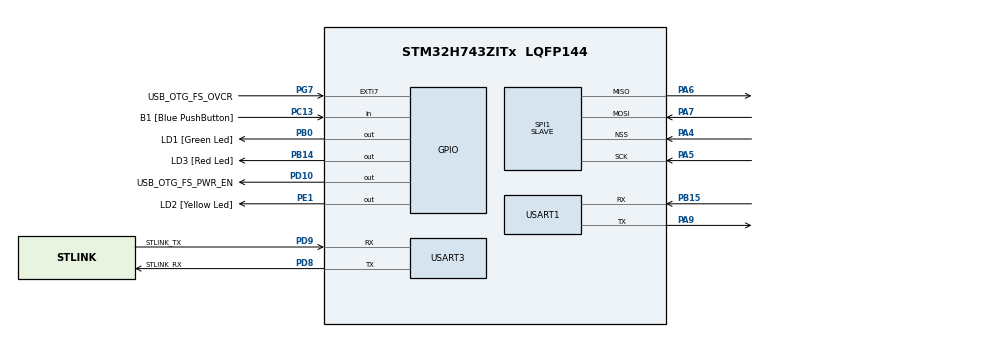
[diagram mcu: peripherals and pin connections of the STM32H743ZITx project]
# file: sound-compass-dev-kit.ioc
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FREERTOS.Queues01=executiveMessageQueue,16,uint16_t,0,Static,executiveMessageQueueBuffer,myQueue01ControlBlock
FREERTOS.Tasks01=defaultTask,24,1024,StartDefaultTask,Default,NULL,Static,defaultTaskBuffer,defaultTaskControlBlock
FREERTOS.Timers01=myTimer01,Callback01,osTimerPeriodic,Default,NULL,Static,myTimer01ControlBlock
FREERTOS.configENABLE_FPU=1
FREERTOS.configUSE_NEWLIB_REENTRANT=1
Mcu.Family=STM32H7
Mcu.Name=STM32H743ZITx
Mcu.Package=LQFP144
NVIC.PriorityGroup=NVIC_PRIORITYGROUP_4
NVIC.SPI1_IRQn=true\:5\:0\:false\:false\:true\:true\:true\:true\:true
NVIC.TIM17_IRQn=true\:15\:0\:false\:false\:true\:false\:false\:true\:true
NVIC.TimeBase=TIM17_IRQn
NVIC.TimeBaseIP=TIM17
PA4.Mode=NSS_Signal_Hard_Input
PA4.Signal=SPI1_NSS
PA5.Mode=Full_Duplex_Slave
PA5.Signal=SPI1_SCK
PA6.Mode=Full_Duplex_Slave
PA6.Signal=SPI1_MISO
PA7.Mode=Full_Duplex_Slave
PA7.Signal=SPI1_MOSI
PA9.Mode=Asynchronous
PA9.Signal=USART1_TX
PB0.GPIO_Label=LD1 [Green Led]
PB0.Signal=GPIO_Output
PB14.GPIO_Label=LD3 [Red Led]
PB14.Signal=GPIO_Output
PB15.Mode=Asynchronous
PB15.Signal=USART1_RX
PC13.GPIO_Label=B1 [Blue PushButton]
PC13.Signal=GPIO_Input
PC14-OSC32_IN\ (OSC32_IN).Mode=LSE-External-Oscillator
PC14-OSC32_IN\ (OSC32_IN).Signal=RCC_OSC32_IN
PC15-OSC32_OUT\ (OSC32_OUT).Mode=LSE-External-Oscillator
PC15-OSC32_OUT\ (OSC32_OUT).Signal=RCC_OSC32_OUT
PD10.GPIO_Label=USB_OTG_FS_PWR_EN
PD10.Signal=GPIO_Output
PD8.GPIO_Label=STLINK_RX
PD8.Mode=Asynchronous
PD8.Signal=USART3_TX
PD9.GPIO_Label=STLINK_TX
PD9.Mode=Asynchronous
PD9.Signal=USART3_RX
PE1.GPIO_Label=LD2 [Yellow Led]
PE1.Signal=GPIO_Output
PG7.GPIO_Label=USB_OTG_FS_OVCR
PG7.Signal=GPXTI7
PH0-OSC_IN\ (PH0).Mode=HSE-External-Clock-Source
PH0-OSC_IN\ (PH0).Signal=RCC_OSC_IN
PH1-OSC_OUT\ (PH1).Signal=RCC_OSC_OUT
ProjectManager.HeapSize=0x200
ProjectManager.StackSize=0x400
ProjectManager.TargetToolchain=STM32CubeIDE
RCC.ADCFreq_Value=16125000
RCC.APB1Freq_Value=120000000
RCC.APB2Freq_Value=120000000
RCC.APB3Freq_Value=120000000
RCC.APB4Freq_Value=120000000
RCC.CortexFreq_Value=480000000
RCC.D1PPRE=RCC_APB3_DIV2
RCC.D2PPRE1=RCC_APB1_DIV2
RCC.D2PPRE2=RCC_APB2_DIV2
RCC.D3PPRE=RCC_APB4_DIV2
RCC.DIVM1=1
RCC.DIVN1=120
RCC.DIVQ1=5
RCC.HCLKFreq_Value=240000000
RCC.HPRE=RCC_HCLK_DIV2
RCC.HSE_VALUE=8000000
RCC.PLLFRACN=0
RCC.PLLSourceVirtual=RCC_PLLSOURCE_HSE
RCC.PWR_Regulator_Voltage_Scale=PWR_REGULATOR_VOLTAGE_SCALE0
RCC.ProductRev=revV
RCC.SYSCLKFreq_VALUE=480000000
RCC.SYSCLKSource=RCC_SYSCLKSOURCE_PLLCLK
RCC.USBFreq_Value=192000000
SPI1.Direction=SPI_DIRECTION_2LINES
SPI1.Mode=SPI_MODE_SLAVE
SPI1.VirtualNSS=VM_NSSHARD
SPI1.VirtualType=VM_SLAVE
USART1.VirtualMode-Asynchronous=VM_ASYNC
USART3.VirtualMode-Asynchronous=VM_ASYNC
VP_FREERTOS_VS_CMSIS_V2.Mode=CMSIS_V2
VP_SYS_VS_tim17.Mode=TIM17
board=NUCLEO-H743ZI2

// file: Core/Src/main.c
/* USER CODE BEGIN Header */
/**
  ******************************************************************************
  * @file           : main.c
  * @brief          : Main program body
  ******************************************************************************
  * @attention
  *
  * Copyright (c) 2023 STMicroelectronics.
  * All rights reserved.
  *
  * This software is licensed under terms that can be found in the LICENSE file
  * in the root directory of this software component.
  * If no LICENSE file comes with this software, it is provided AS-IS.
  *
  ******************************************************************************
  */
/* USER CODE END Header */
#include "main.h"
#include "cmsis_os.h"

typedef StaticTask_t osStaticThreadDef_t;
typedef StaticQueue_t osStaticMessageQDef_t;
typedef StaticTimer_t osStaticTimerDef_t;

SPI_HandleTypeDef hspi1;

UART_HandleTypeDef huart1;
UART_HandleTypeDef huart3;

/* Definitions for defaultTask */
osThreadId_t defaultTaskHandle;
uint32_t defaultTaskBuffer[ 1024 ];
osStaticThreadDef_t defaultTaskControlBlock;
const osThreadAttr_t defaultTask_attributes = {
  .name = "defaultTask",
  .cb_mem = &defaultTaskControlBlock,
  .cb_size = sizeof(defaultTaskControlBlock),
  .stack_mem = &defaultTaskBuffer[0],
  .stack_size = sizeof(defaultTaskBuffer),
  .priority = (osPriority_t) osPriorityNormal,
};
/* Definitions for executiveMessageQueue */
osMessageQueueId_t executiveMessageQueueHandle;
uint8_t executiveMessageQueueBuffer[ 16 * sizeof( uint16_t ) ];
osStaticMessageQDef_t myQueue01ControlBlock;
const osMessageQueueAttr_t executiveMessageQueue_attributes = {
  .name = "executiveMessageQueue",
  .cb_mem = &myQueue01ControlBlock,
  .cb_size = sizeof(myQueue01ControlBlock),
  .mq_mem = &executiveMessageQueueBuffer,
  .mq_size = sizeof(executiveMessageQueueBuffer)
};
/* Definitions for myTimer01 */
osTimerId_t myTimer01Handle;
osStaticTimerDef_t myTimer01ControlBlock;
const osTimerAttr_t myTimer01_attributes = {
  .name = "myTimer01",
  .cb_mem = &myTimer01ControlBlock,
  .cb_size = sizeof(myTimer01ControlBlock),
};

void SystemClock_Config(void);
static void MX_GPIO_Init(void);
static void MX_SPI1_Init(void);
static void MX_USART3_UART_Init(void);
static void MX_USART1_UART_Init(void);
void StartDefaultTask(void *argument);
void Callback01(void *argument);

int main(void)
{

  /* MCU Configuration--------------------------------------------------------*/

  /* Reset of all peripherals, Initializes the Flash interface and the Systick. */
  HAL_Init();

  /* Configure the system clock */
  SystemClock_Config();

  /* Initialize all configured peripherals */
  MX_GPIO_Init();
  MX_SPI1_Init();
  MX_USART3_UART_Init();
  MX_USART1_UART_Init();

  /* Init scheduler */
  osKernelInitialize();

  /* Create the timer(s) */
  /* creation of myTimer01 */
  myTimer01Handle = osTimerNew(Callback01, osTimerPeriodic, NULL, &myTimer01_attributes);

  /* Create the queue(s) */
  /* creation of executiveMessageQueue */
  executiveMessageQueueHandle = osMessageQueueNew (16, sizeof(uint16_t), &executiveMessageQueue_attributes);

  /* Create the thread(s) */
  /* creation of defaultTask */
  defaultTaskHandle = osThreadNew(StartDefaultTask, NULL, &defaultTask_attributes);

  /* Start scheduler */
  osKernelStart();

  /* We should never get here as control is now taken by the scheduler */
  /* Infinite loop */
  while (1)
  {

  }
}

void SystemClock_Config(void)
{
  RCC_OscInitTypeDef RCC_OscInitStruct = {0};
  RCC_ClkInitTypeDef RCC_ClkInitStruct = {0};

  /** Supply configuration update enable
  */
  HAL_PWREx_ConfigSupply(PWR_LDO_SUPPLY);

  /** Configure the main internal regulator output voltage
  */
  __HAL_PWR_VOLTAGESCALING_CONFIG(PWR_REGULATOR_VOLTAGE_SCALE1);

  while(!__HAL_PWR_GET_FLAG(PWR_FLAG_VOSRDY)) {}

  __HAL_RCC_SYSCFG_CLK_ENABLE();
  __HAL_PWR_VOLTAGESCALING_CONFIG(PWR_REGULATOR_VOLTAGE_SCALE0);

  while(!__HAL_PWR_GET_FLAG(PWR_FLAG_VOSRDY)) {}

  /** Initializes the RCC Oscillators according to the specified parameters
  * in the RCC_OscInitTypeDef structure.
  */
  RCC_OscInitStruct.OscillatorType = RCC_OSCILLATORTYPE_HSE;
  RCC_OscInitStruct.HSEState = RCC_HSE_BYPASS;
  RCC_OscInitStruct.PLL.PLLState = RCC_PLL_ON;
  RCC_OscInitStruct.PLL.PLLSource = RCC_PLLSOURCE_HSE;
  RCC_OscInitStruct.PLL.PLLM = 1;
  RCC_OscInitStruct.PLL.PLLN = 120;
  RCC_OscInitStruct.PLL.PLLP = 2;
  RCC_OscInitStruct.PLL.PLLQ = 5;
  RCC_OscInitStruct.PLL.PLLR = 2;
  RCC_OscInitStruct.PLL.PLLRGE = RCC_PLL1VCIRANGE_3;
  RCC_OscInitStruct.PLL.PLLVCOSEL = RCC_PLL1VCOWIDE;
  RCC_OscInitStruct.PLL.PLLFRACN = 0;
  if (HAL_RCC_OscConfig(&RCC_OscInitStruct) != HAL_OK)
  {
    Error_Handler();
  }

  /** Initializes the CPU, AHB and APB buses clocks
  */
  RCC_ClkInitStruct.ClockType = RCC_CLOCKTYPE_HCLK|RCC_CLOCKTYPE_SYSCLK
                              |RCC_CLOCKTYPE_PCLK1|RCC_CLOCKTYPE_PCLK2
                              |RCC_CLOCKTYPE_D3PCLK1|RCC_CLOCKTYPE_D1PCLK1;
  RCC_ClkInitStruct.SYSCLKSource = RCC_SYSCLKSOURCE_PLLCLK;
  RCC_ClkInitStruct.SYSCLKDivider = RCC_SYSCLK_DIV1;
  RCC_ClkInitStruct.AHBCLKDivider = RCC_HCLK_DIV2;
  RCC_ClkInitStruct.APB3CLKDivider = RCC_APB3_DIV2;
  RCC_ClkInitStruct.APB1CLKDivider = RCC_APB1_DIV2;
  RCC_ClkInitStruct.APB2CLKDivider = RCC_APB2_DIV2;
  RCC_ClkInitStruct.APB4CLKDivider = RCC_APB4_DIV2;

  if (HAL_RCC_ClockConfig(&RCC_ClkInitStruct, FLASH_LATENCY_4) != HAL_OK)
  {
    Error_Handler();
  }
}

static void MX_SPI1_Init(void)
{

  /* SPI1 parameter configuration*/
  hspi1.Instance = SPI1;
  hspi1.Init.Mode = SPI_MODE_SLAVE;
  hspi1.Init.Direction = SPI_DIRECTION_2LINES;
  hspi1.Init.DataSize = SPI_DATASIZE_4BIT;
  hspi1.Init.CLKPolarity = SPI_POLARITY_LOW;
  hspi1.Init.CLKPhase = SPI_PHASE_1EDGE;
  hspi1.Init.NSS = SPI_NSS_HARD_INPUT;
  hspi1.Init.FirstBit = SPI_FIRSTBIT_MSB;
  hspi1.Init.TIMode = SPI_TIMODE_DISABLE;
  hspi1.Init.CRCCalculation = SPI_CRCCALCULATION_DISABLE;
  hspi1.Init.CRCPolynomial = 0x0;
  hspi1.Init.NSSPMode = SPI_NSS_PULSE_DISABLE;
  hspi1.Init.NSSPolarity = SPI_NSS_POLARITY_LOW;
  hspi1.Init.FifoThreshold = SPI_FIFO_THRESHOLD_01DATA;
  hspi1.Init.TxCRCInitializationPattern = SPI_CRC_INITIALIZATION_ALL_ZERO_PATTERN;
  hspi1.Init.RxCRCInitializationPattern = SPI_CRC_INITIALIZATION_ALL_ZERO_PATTERN;
  hspi1.Init.MasterSSIdleness = SPI_MASTER_SS_IDLENESS_00CYCLE;
  hspi1.Init.MasterInterDataIdleness = SPI_MASTER_INTERDATA_IDLENESS_00CYCLE;
  hspi1.Init.MasterReceiverAutoSusp = SPI_MASTER_RX_AUTOSUSP_DISABLE;
  hspi1.Init.MasterKeepIOState = SPI_MASTER_KEEP_IO_STATE_DISABLE;
  hspi1.Init.IOSwap = SPI_IO_SWAP_DISABLE;
  if (HAL_SPI_Init(&hspi1) != HAL_OK)
  {
    Error_Handler();
  }

}

static void MX_USART1_UART_Init(void)
{

  huart1.Instance = USART1;
  huart1.Init.BaudRate = 115200;
  huart1.Init.WordLength = UART_WORDLENGTH_8B;
  huart1.Init.StopBits = UART_STOPBITS_1;
  huart1.Init.Parity = UART_PARITY_NONE;
  huart1.Init.Mode = UART_MODE_TX_RX;
  huart1.Init.HwFlowCtl = UART_HWCONTROL_NONE;
  huart1.Init.OverSampling = UART_OVERSAMPLING_16;
  huart1.Init.OneBitSampling = UART_ONE_BIT_SAMPLE_DISABLE;
  huart1.Init.ClockPrescaler = UART_PRESCALER_DIV1;
  huart1.AdvancedInit.AdvFeatureInit = UART_ADVFEATURE_NO_INIT;
  if (HAL_UART_Init(&huart1) != HAL_OK)
  {
    Error_Handler();
  }
  if (HAL_UARTEx_SetTxFifoThreshold(&huart1, UART_TXFIFO_THRESHOLD_1_8) != HAL_OK)
  {
    Error_Handler();
  }
  if (HAL_UARTEx_SetRxFifoThreshold(&huart1, UART_RXFIFO_THRESHOLD_1_8) != HAL_OK)
  {
    Error_Handler();
  }
  if (HAL_UARTEx_DisableFifoMode(&huart1) != HAL_OK)
  {
    Error_Handler();
  }

}

static void MX_USART3_UART_Init(void)
{

  huart3.Instance = USART3;
  huart3.Init.BaudRate = 115200;
  huart3.Init.WordLength = UART_WORDLENGTH_8B;
  huart3.Init.StopBits = UART_STOPBITS_1;
  huart3.Init.Parity = UART_PARITY_NONE;
  huart3.Init.Mode = UART_MODE_TX_RX;
  huart3.Init.HwFlowCtl = UART_HWCONTROL_NONE;
  huart3.Init.OverSampling = UART_OVERSAMPLING_16;
  huart3.Init.OneBitSampling = UART_ONE_BIT_SAMPLE_DISABLE;
  huart3.Init.ClockPrescaler = UART_PRESCALER_DIV1;
  huart3.AdvancedInit.AdvFeatureInit = UART_ADVFEATURE_NO_INIT;
  if (HAL_UART_Init(&huart3) != HAL_OK)
  {
    Error_Handler();
  }
  if (HAL_UARTEx_SetTxFifoThreshold(&huart3, UART_TXFIFO_THRESHOLD_1_8) != HAL_OK)
  {
    Error_Handler();
  }
  if (HAL_UARTEx_SetRxFifoThreshold(&huart3, UART_RXFIFO_THRESHOLD_1_8) != HAL_OK)
  {
    Error_Handler();
  }
  if (HAL_UARTEx_DisableFifoMode(&huart3) != HAL_OK)
  {
    Error_Handler();
  }

}

static void MX_GPIO_Init(void)
{
  GPIO_InitTypeDef GPIO_InitStruct = {0};

  /* GPIO Ports Clock Enable */
  __HAL_RCC_GPIOC_CLK_ENABLE();
  __HAL_RCC_GPIOH_CLK_ENABLE();
  __HAL_RCC_GPIOA_CLK_ENABLE();
  __HAL_RCC_GPIOB_CLK_ENABLE();
  __HAL_RCC_GPIOD_CLK_ENABLE();
  __HAL_RCC_GPIOG_CLK_ENABLE();
  __HAL_RCC_GPIOE_CLK_ENABLE();

  /*Configure GPIO pin Output Level */
  HAL_GPIO_WritePin(GPIOB, LD1_Pin|LD3_Pin, GPIO_PIN_RESET);

  /*Configure GPIO pin Output Level */
  HAL_GPIO_WritePin(USB_OTG_FS_PWR_EN_GPIO_Port, USB_OTG_FS_PWR_EN_Pin, GPIO_PIN_RESET);

  /*Configure GPIO pin Output Level */
  HAL_GPIO_WritePin(LD2_GPIO_Port, LD2_Pin, GPIO_PIN_RESET);

  /*Configure GPIO pin : B1_Pin */
  GPIO_InitStruct.Pin = B1_Pin;
  GPIO_InitStruct.Mode = GPIO_MODE_INPUT;
  GPIO_InitStruct.Pull = GPIO_NOPULL;
  HAL_GPIO_Init(B1_GPIO_Port, &GPIO_InitStruct);

  /*Configure GPIO pins : LD1_Pin LD3_Pin */
  GPIO_InitStruct.Pin = LD1_Pin|LD3_Pin;
  GPIO_InitStruct.Mode = GPIO_MODE_OUTPUT_PP;
  GPIO_InitStruct.Pull = GPIO_NOPULL;
  GPIO_InitStruct.Speed = GPIO_SPEED_FREQ_LOW;
  HAL_GPIO_Init(GPIOB, &GPIO_InitStruct);

  /*Configure GPIO pin : USB_OTG_FS_PWR_EN_Pin */
  GPIO_InitStruct.Pin = USB_OTG_FS_PWR_EN_Pin;
  GPIO_InitStruct.Mode = GPIO_MODE_OUTPUT_PP;
  GPIO_InitStruct.Pull = GPIO_NOPULL;
  GPIO_InitStruct.Speed = GPIO_SPEED_FREQ_LOW;
  HAL_GPIO_Init(USB_OTG_FS_PWR_EN_GPIO_Port, &GPIO_InitStruct);

  /*Configure GPIO pin : USB_OTG_FS_OVCR_Pin */
  GPIO_InitStruct.Pin = USB_OTG_FS_OVCR_Pin;
  GPIO_InitStruct.Mode = GPIO_MODE_IT_RISING;
  GPIO_InitStruct.Pull = GPIO_NOPULL;
  HAL_GPIO_Init(USB_OTG_FS_OVCR_GPIO_Port, &GPIO_InitStruct);

  /*Configure GPIO pin : LD2_Pin */
  GPIO_InitStruct.Pin = LD2_Pin;
  GPIO_InitStruct.Mode = GPIO_MODE_OUTPUT_PP;
  GPIO_InitStruct.Pull = GPIO_NOPULL;
  GPIO_InitStruct.Speed = GPIO_SPEED_FREQ_LOW;
  HAL_GPIO_Init(LD2_GPIO_Port, &GPIO_InitStruct);

}

/* USER CODE BEGIN Header_StartDefaultTask */

extern void executiveStart_c(void);

/**
  * @brief  Function implementing the defaultTask thread.
  * @param  argument: Not used
  * @retval None
  */
/* USER CODE END Header_StartDefaultTask */
void StartDefaultTask(void *argument)
{
  /* USER CODE BEGIN 5 */
  /* Infinite loop */
  for(;;)
  {
	  executiveStart_c();
    osDelay(1);
  }
  /* USER CODE END 5 */
}

/* Callback01 function */
void Callback01(void *argument)
{
}

void HAL_TIM_PeriodElapsedCallback(TIM_HandleTypeDef *htim)
{
  if (htim->Instance == TIM17) {
    HAL_IncTick();
  }
}

void Error_Handler(void)
{
  __disable_irq();
  while (1)
  {
  }
}
